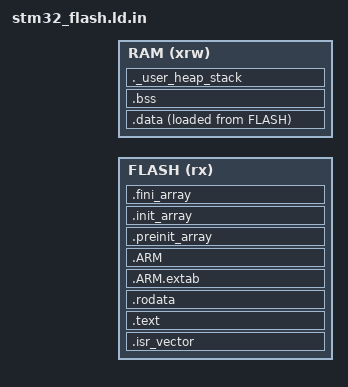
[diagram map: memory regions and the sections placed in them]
/* Generated from cmake/stm32_flash.ld.in -- edit that, not the copy in build/.
 * Memory numbers come from config.cmake, which setup.py fills from the
 * device's CMSIS-Pack.
 */

ENTRY(Reset_Handler)

MEMORY
{
  FLASH (rx)  : ORIGIN = @FLASH_ORIGIN@, LENGTH = @FLASH_SIZE@
  RAM   (xrw) : ORIGIN = @RAM_ORIGIN@,   LENGTH = @RAM_SIZE@
}

/* Full descending stack, so it starts at the top of RAM and grows down. */
_estack     = ORIGIN(RAM) + LENGTH(RAM);
_Min_Heap_Size  = @HEAP_SIZE@;
_Min_Stack_Size = @STACK_SIZE@;

SECTIONS
{
  .isr_vector :
  {
    . = ALIGN(4);
    KEEP(*(.isr_vector))
    . = ALIGN(4);
  } >FLASH

  .text :
  {
    . = ALIGN(4);
    *(.text)
    *(.text*)
    *(.glue_7)
    *(.glue_7t)
    *(.eh_frame)
    KEEP(*(.init))
    KEEP(*(.fini))
    . = ALIGN(4);
    _etext = .;
  } >FLASH

  .rodata :
  {
    . = ALIGN(4);
    *(.rodata)
    *(.rodata*)
    . = ALIGN(4);
  } >FLASH

  .ARM.extab : { *(.ARM.extab* .gnu.linkonce.armextab.*) } >FLASH
  .ARM : {
    __exidx_start = .;
    *(.ARM.exidx*)
    __exidx_end = .;
  } >FLASH

  .preinit_array : {
    PROVIDE_HIDDEN (__preinit_array_start = .);
    KEEP(*(.preinit_array*))
    PROVIDE_HIDDEN (__preinit_array_end = .);
  } >FLASH
  .init_array : {
    PROVIDE_HIDDEN (__init_array_start = .);
    KEEP(*(SORT(.init_array.*)))
    KEEP(*(.init_array*))
    PROVIDE_HIDDEN (__init_array_end = .);
  } >FLASH
  .fini_array : {
    PROVIDE_HIDDEN (__fini_array_start = .);
    KEEP(*(SORT(.fini_array.*)))
    KEEP(*(.fini_array*))
    PROVIDE_HIDDEN (__fini_array_end = .);
  } >FLASH

  /* Initialised data: lives in FLASH, copied into RAM by Reset_Handler. */
  _sidata = LOADADDR(.data);
  .data :
  {
    . = ALIGN(4);
    _sdata = .;
    *(.data)
    *(.data*)
    *(.RamFunc)
    *(.RamFunc*)
    . = ALIGN(4);
    _edata = .;
  } >RAM AT> FLASH

  . = ALIGN(4);
  .bss :
  {
    _sbss = .;
    __bss_start__ = _sbss;
    *(.bss)
    *(.bss*)
    *(COMMON)
    . = ALIGN(4);
    _ebss = .;
    __bss_end__ = _ebss;
  } >RAM

  /* Not emitted, but it makes the link fail instead of silently overflowing
   * the stack at runtime when RAM runs out. */
  ._user_heap_stack :
  {
    . = ALIGN(8);
    PROVIDE ( end = . );
    PROVIDE ( _end = . );
    . = . + _Min_Heap_Size;
    . = . + _Min_Stack_Size;
    . = ALIGN(8);
  } >RAM

  /DISCARD/ : { libc.a ( * ) libm.a ( * ) libgcc.a ( * ) }

  .ARM.attributes 0 : { *(.ARM.attributes) }
}
